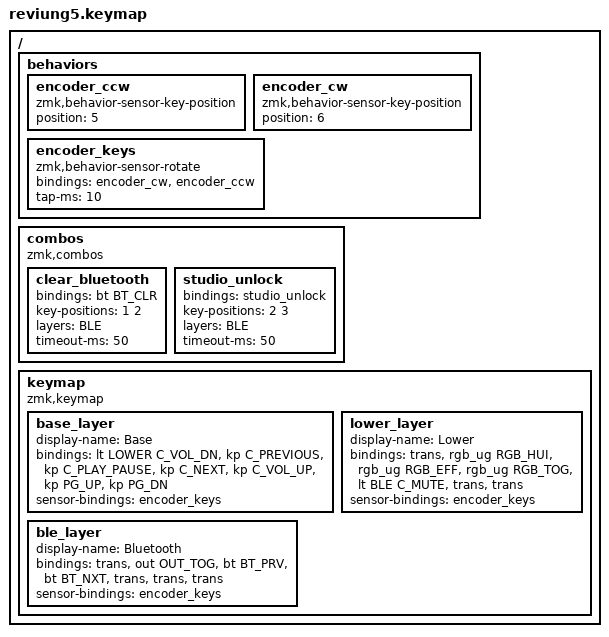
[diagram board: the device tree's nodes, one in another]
/*
 * Copyright (c) 2026 The ZMK Contributors
 *
 * SPDX-License-Identifier: MIT
 */

#include <behaviors.dtsi>
#include <dt-bindings/zmk/keys.h>
#include <dt-bindings/zmk/bt.h>
#include <dt-bindings/zmk/outputs.h>
#include <dt-bindings/zmk/rgb.h>

#define BASE 0
#define LOWER 1
#define BLE 2

/ {
    behaviors {
        encoder_ccw: encoder_ccw {
            compatible = "zmk,behavior-sensor-key-position";
            #binding-cells = <0>;
            position = <5>;
        };

        encoder_cw: encoder_cw {
            compatible = "zmk,behavior-sensor-key-position";
            #binding-cells = <0>;
            position = <6>;
        };

        encoder_keys: encoder_keys {
            compatible = "zmk,behavior-sensor-rotate";
            #sensor-binding-cells = <0>;
            bindings = <&encoder_cw>, <&encoder_ccw>;
            tap-ms = <10>;
        };
    };

    combos {
        compatible = "zmk,combos";

        clear_bluetooth {
            bindings = <&bt BT_CLR>;
            key-positions = <1 2>;
            layers = <BLE>;
            timeout-ms = <50>;
        };

        studio_unlock {
            bindings = <&studio_unlock>;
            key-positions = <2 3>;
            layers = <BLE>;
            timeout-ms = <50>;
        };
    };

    keymap {
        compatible = "zmk,keymap";

        base_layer {
            display-name = "Base";
            // Tap volume down; hold for Lower.
            bindings = <
                &lt LOWER C_VOL_DN &kp C_PREVIOUS &kp C_PLAY_PAUSE &kp C_NEXT &kp C_VOL_UP   &kp PG_UP &kp PG_DN
            >;
            sensor-bindings = <&encoder_keys>;
        };

        lower_layer {
            display-name = "Lower";
            // Tap mute as in QMK; hold for Bluetooth/output controls.
            bindings = <
                &trans &rgb_ug RGB_HUI &rgb_ug RGB_EFF &rgb_ug RGB_TOG &lt BLE C_MUTE   &trans &trans
            >;
            sensor-bindings = <&encoder_keys>;
        };

        ble_layer {
            display-name = "Bluetooth";
            bindings = <
                &trans &out OUT_TOG &bt BT_PRV &bt BT_NXT &trans   &trans &trans
            >;
            sensor-bindings = <&encoder_keys>;
        };
    };
};
